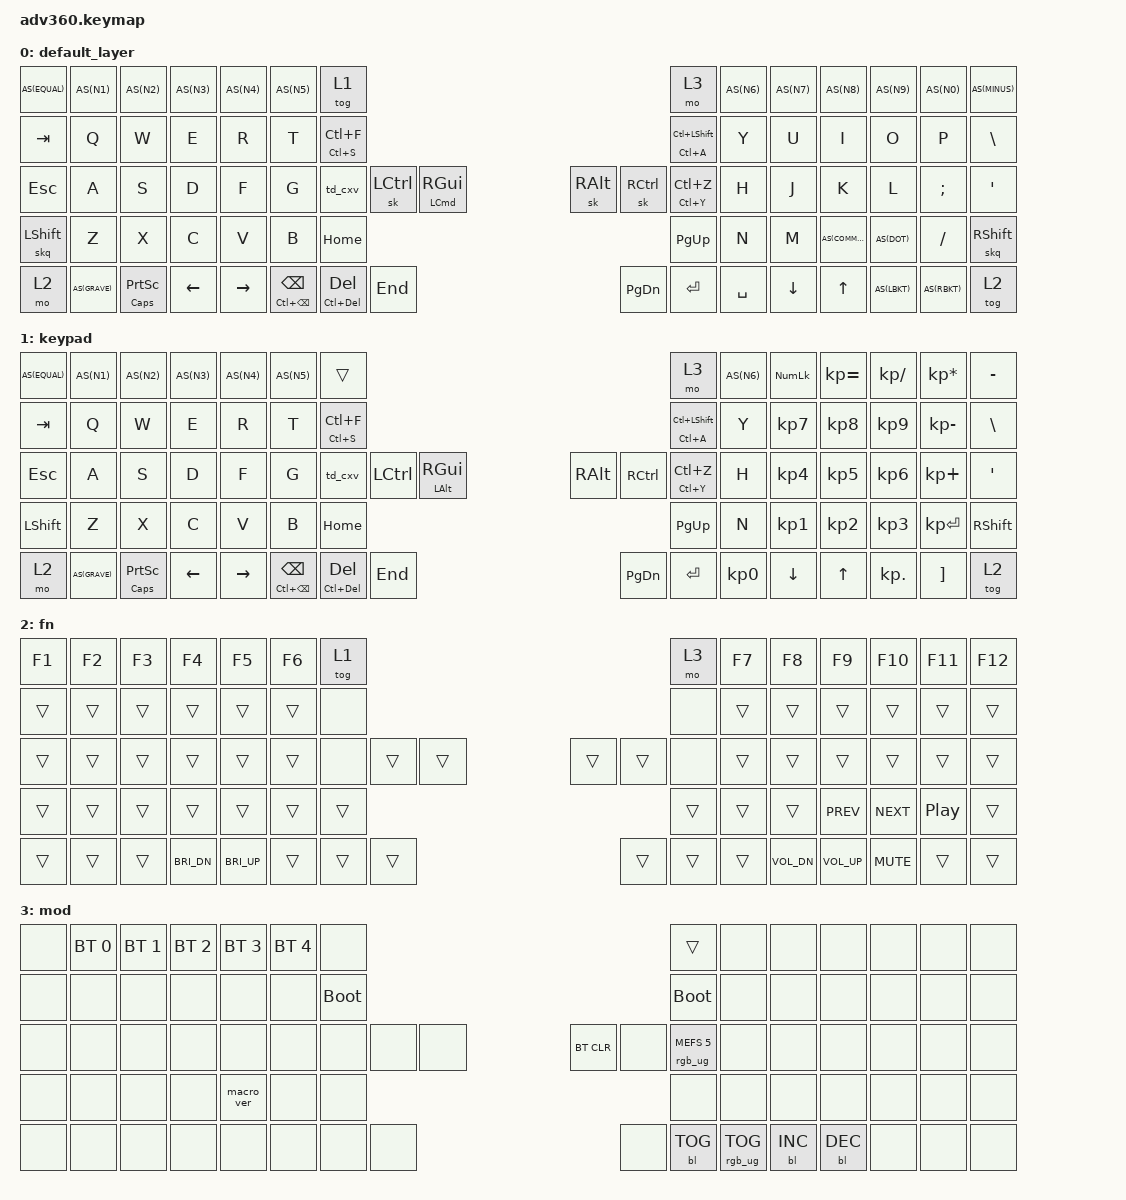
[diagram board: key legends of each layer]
#include <behaviors.dtsi>
#include <dt-bindings/zmk/keys.h>
#include <dt-bindings/zmk/bt.h>
#include <dt-bindings/zmk/rgb.h>
#include <dt-bindings/zmk/backlight.h>

#define AS(keycode) &as LS(keycode) keycode     // Autoshift Macro
#define COMBO(NAME, BINDINGS, KEYPOS) \
  combo_##NAME { \
    timeout-ms = <150>; \
    bindings = <BINDINGS>; \
    key-positions = <KEYPOS>; \
    layers = <0>; \
  };

&caps_word {
  continue-list = <BACKSPACE DELETE UNDERSCORE MINUS COMMA DOT SLASH PIPE BACKSLASH>;
};

/ {
    combos {
        compatible = "zmk,combos";
        COMBO(caps, &caps_word, 28 45) 

        // 28:ESC  45:quotes
        // 46:LSHIFT  65:RSHIFT 

      /* 
        combo_caps {
            timeout-ms = <50>;
            key-positions = <0 1>;
            bindings = <&caps_word>;
        }; 
      */
    };
    
    behaviors {
      #include "macros.dtsi"
      #include "version.dtsi"
      #ifndef VERSION_MACRO
      macro_ver: macro_ver {
        compatible = "zmk,behavior-macro";
        label = "macro_version";
        #binding-cells = <0>;
        bindings = <&kp RET>;
      };
      #endif

      
      hm: homerow_mods {
          compatible = "zmk,behavior-hold-tap";
          label = "HOMEROW_MODS";
          #binding-cells = <2>;
          tapping-term-ms = <200>;
          quick_tap_ms = <175>;
          flavor = "tap-preferred";
          bindings = <&kp>, <&kp>;
      };
      as: auto_shift {
          compatible = "zmk,behavior-hold-tap";
          label = "AUTO_SHIFT";
          #binding-cells = <2>;
          tapping_term_ms = <200>;
          quick_tap_ms = <0>;
          flavor = "tap-preferred";
          bindings = <&kp>, <&kp>;
      };
      htp: hold-tap-preferred {
          compatible = "zmk,behavior-hold-tap";
          label = "HOLDTAP_TAP_PREFERRED";
          #binding-cells = <2>;
          tapping_term_ms = <200>;
          quick_tap_ms = <0>;
          flavor = "tap-preferred";
          bindings = <&kp>, <&kp>;
      };
      lhtp: longhold-tap-preferred {
          compatible = "zmk,behavior-hold-tap";
          label = "LONGHOLDTAP_TAP_PREFERRED";
          #binding-cells = <2>;
          tapping_term_ms = <300>;
          quick_tap_ms = <0>;
          flavor = "tap-preferred";
          bindings = <&kp>, <&kp>;
      };
      hts: hold-sticky-tap-preferred {
          compatible = "zmk,behavior-hold-tap";
          label = "HOLDSTICKY_TAP_PREFERRED";
          #binding-cells = <2>;
          tapping_term_ms = <200>;
          quick_tap_ms = <0>;
          flavor = "tap-preferred";
          bindings = <&kp>, <&sk>;
      };
      td_cxv: tap_dance_cxv {
          compatible = "zmk,behavior-tap-dance";
          label = "TAP_DANCE_CXV";
          #binding-cells = <0>;
          tapping-term-ms = <200>;
          bindings = <&kp LC(C)>, <&htp LC(V) LC(X)>;
      };
      skq: sticky_key_quick_release {
        compatible = "zmk,behavior-sticky-key";
        label = "STICKY_KEY_QUICK";
        #binding-cells = <1>;
        bindings = <&kp>;
        release-after-ms = <1000>;
        quick-release;
        ignore-modifiers;
      };
    };

  keymap {
    compatible = "zmk,keymap";

    default_layer {
      bindings = <
        AS(EQUAL) AS(N1)    AS(N2)          AS(N3)   AS(N4)     AS(N5) &tog 1                                                                                                 &mo 3                 AS(N6) AS(N7)    AS(N8)    AS(N9)   AS(N0)   AS(MINUS)
        &kp TAB   &kp Q     &kp W           &kp E    &kp R      &kp T  &htp LC(S) LC(F)                                                                                       &hts LC(A) LC(LSHIFT) &kp Y  &kp U     &kp I     &kp O    &kp P    &kp BSLH
        &kp ESC   &kp A     &kp S           &kp D    &kp F      &kp G  &td_cxv                     &sk LCTRL        &lhtp LCMD RGUI             &sk RALT  &sk RCTRL           &htp LC(Y) LC(Z)      &kp H  &kp J     &kp K     &kp L    &kp SEMI &kp SQT
        &skq LSHFT &kp Z     &kp X           &kp C    &kp V      &kp B                                               &kp HOME                    &kp PG_UP                                           &kp N  &kp M     AS(COMMA) AS(DOT)  &kp FSLH &skq RSHFT
        &mo 2     AS(GRAVE) &htp CAPS PSCRN &kp LEFT &kp RIGHT                 &htp LC(BSPC) BSPC  &htp LC(DEL) DEL &kp END                     &kp PG_DN &kp ENTER &kp SPACE                              &kp DOWN  &kp UP    AS(LBKT) AS(RBKT) &tog 2
      >;
    };
    keypad {
      bindings = <
        AS(EQUAL) AS(N1)    AS(N2)          AS(N3)   AS(N4)     AS(N5) &trans                                                                                                  &mo 3                 AS(N6) &kp KP_NUM &kp KP_EQUAL &kp KP_DIVIDE &kp KP_MULTIPLY &kp MINUS
        &kp TAB   &kp Q     &kp W           &kp E    &kp R      &kp T  &htp LC(S) LC(F)                                                                                        &hts LC(A) LC(LSHIFT) &kp Y  &kp KP_N7  &kp KP_N8    &kp KP_N9     &kp KP_MINUS    &kp BSLH
        &kp ESC   &kp A     &kp S           &kp D    &kp F      &kp G  &td_cxv                     &kp LCTRL        &lhtp LALT RGUI             &kp RALT  &kp RCTRL            &htp LC(Y) LC(Z)      &kp H  &kp KP_N4  &kp KP_N5    &kp KP_N6     &kp KP_PLUS     &kp SQT
        &kp LSHFT &kp Z     &kp X           &kp C    &kp V      &kp B                                               &kp HOME                    &kp PG_UP                                            &kp N  &kp KP_N1  &kp KP_N2    &kp KP_N3     &kp KP_ENTER    &kp RSHFT
        &mo 2     AS(GRAVE) &htp CAPS PSCRN &kp LEFT &kp RIGHT                 &htp LC(BSPC) BSPC  &htp LC(DEL) DEL &kp END                     &kp PG_DN &kp ENTER &kp KP_N0                               &kp DOWN   &kp UP       &kp KP_DOT    &kp RBKT        &tog 2
      >;
    }; 
    fn {
      bindings = <
        &kp F1 &kp F2 &kp F3    &kp F4       &kp F5       &kp F6  &tog 1                                                      &mo 3 &kp F7 &kp F8        &kp F9        &kp F10     &kp F11  &kp F12
        &trans &trans &trans    &trans       &trans       &trans  &none                                                       &none &trans &trans        &trans        &trans      &trans   &trans
        &trans &trans &trans    &trans       &trans       &trans  &none        &trans &trans             &trans &trans        &none &trans &trans        &trans        &trans      &trans   &trans
        &trans &trans &trans    &trans       &trans       &trans                      &trans             &trans                     &trans &trans        &kp C_PREV    &kp C_NEXT  &kp C_PP &trans
        &trans &trans &trans    &kp C_BRI_DN &kp C_BRI_UP               &trans &trans &trans             &trans &trans &trans              &kp C_VOL_DN  &kp C_VOL_UP  &kp C_MUTE  &trans   &trans
      >;
    };
    mod {
      bindings = <
        &none &bt BT_SEL 0 &bt BT_SEL 1 &bt BT_SEL 2 &bt BT_SEL 3 &bt BT_SEL 4 &none                                                                     &trans                 &none        &none        &none        &none &none &none
        &none &none        &none        &none        &none        &none        &bootloader                                                               &bootloader            &none        &none        &none        &none &none &none
        &none &none        &none        &none        &none        &none        &none                   &none &none &bt BT_CLR &none                      &rgb_ug RGB_MEFS_CMD 5 &none        &none        &none        &none &none &none
        &none &none        &none        &none        &macro_ver   &none                                      &none &none                                                        &none        &none        &none        &none &none &none
        &none &none        &none        &none        &none                                       &none &none &none &none      &bl BL_TOG &rgb_ug RGB_TOG                                     &bl BL_INC   &bl BL_DEC   &none &none &none
      >;
    };
  };
};
